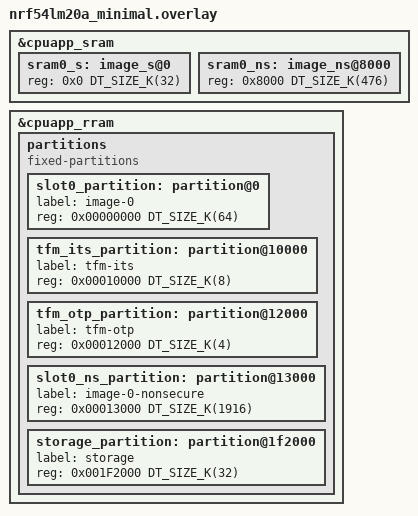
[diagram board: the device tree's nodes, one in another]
/*
 * Copyright (c) 2026 Nordic Semiconductor ASA
 *
 * SPDX-License-Identifier: LicenseRef-Nordic-5-Clause
 */

/*
 * Minimal TF-M partition layout for nRF54LM20A
 *
 * nRF54LM20A has 2036 kB of RRAM and 512 kB of SRAM (508 kB usable).
 * TrustZone flash region alignment: 4 kB (MPC-based)
 * TrustZone RAM region alignment:   4 kB
 * RRAM erase-block-size:            4 kB
 *
 * This is the largest nRF54L-family SoC. The generous memory allows
 * even a minimal profile to leave substantial space for the
 * non-secure application.
 *
 * This layout uses the TF-M minimal profile with:
 * - No MCUboot (direct boot)
 * - No Protected Storage
 * - Minimal ITS and OTP
 * - Maximized non-secure application space (~1916 kB)
 *
 * Suitable for: development, large-footprint applications with
 *               minimal security requirements
 */

&cpuapp_sram {
	sram0_s: image_s@0 {
		#address-cells = <1>;
		#size-cells = <1>;
		reg = <0x0 DT_SIZE_K(32)>;
		ranges = <0x0 0x0 DT_SIZE_K(32)>;
	};

	sram0_ns: image_ns@8000 {
		#address-cells = <1>;
		#size-cells = <1>;
		reg = <0x8000 DT_SIZE_K(476)>;
		ranges = <0x0 0x8000 DT_SIZE_K(476)>;
	};
};

&cpuapp_rram {
	partitions {
		compatible = "fixed-partitions";
		#address-cells = <1>;
		#size-cells = <1>;

		/*
		 * Flash layout (all addresses 4 kB aligned):
		 *
		 * 0x00000000  TF-M secure image         (64 kB)
		 * 0x00010000  TF-M ITS                    (8 kB)
		 * 0x00012000  TF-M OTP / NV counters      (4 kB)
		 * 0x00013000  Non-secure application   (1916 kB)
		 * 0x001F2000  Non-secure storage          (32 kB)
		 *
		 * Total: 64 + 8 + 4 + 1916 + 32 = 2024 kB (within 2036 kB)
		 */

		slot0_partition: partition@0 {
			label = "image-0";
			reg = <0x00000000 DT_SIZE_K(64)>;
		};

		tfm_its_partition: partition@10000 {
			label = "tfm-its";
			reg = <0x00010000 DT_SIZE_K(8)>;
		};

		tfm_otp_partition: partition@12000 {
			label = "tfm-otp";
			reg = <0x00012000 DT_SIZE_K(4)>;
		};

		slot0_ns_partition: partition@13000 {
			label = "image-0-nonsecure";
			reg = <0x00013000 DT_SIZE_K(1916)>;
		};

		storage_partition: partition@1f2000 {
			label = "storage";
			reg = <0x001F2000 DT_SIZE_K(32)>;
		};
	};
};
